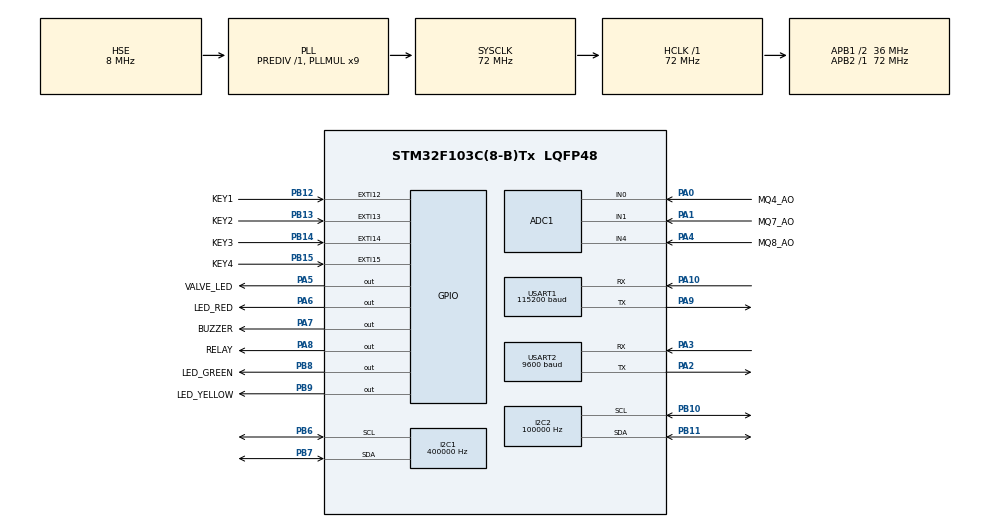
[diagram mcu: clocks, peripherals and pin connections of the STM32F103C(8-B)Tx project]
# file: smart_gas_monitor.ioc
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ADC1.Channel-0\#ChannelRegularConversion=ADC_CHANNEL_0
ADC1.NbrOfConversionFlag=1
ADC1.Rank-0\#ChannelRegularConversion=1
ADC1.SamplingTime-0\#ChannelRegularConversion=ADC_SAMPLETIME_239CYCLES_5
ADC1.master=1
I2C1.ClockSpeed=400000
I2C2.ClockSpeed=100000
Mcu.Family=STM32F1
Mcu.Name=STM32F103C(8-B)Tx
Mcu.Package=LQFP48
NVIC.EXTI15_10_IRQn=true\:0\:0\:false\:false\:true\:false\:true\:true
NVIC.PriorityGroup=NVIC_PRIORITYGROUP_4
NVIC.TIM2_IRQn=true\:1\:0\:false\:false\:true\:false\:true\:true
NVIC.USART1_IRQn=true\:2\:0\:false\:false\:true\:false\:true\:true
NVIC.USART2_IRQn=true\:2\:0\:false\:false\:true\:false\:true\:true
PA0-WKUP.GPIO_Label=MQ4_AO
PA0-WKUP.Signal=ADCx_IN0
PA1.GPIO_Label=MQ7_AO
PA1.Signal=ADCx_IN1
PA10.Mode=Asynchronous
PA10.Signal=USART1_RX
PA13.Mode=Serial_Wire
PA13.Signal=SYS_JTMS-SWDIO
PA14.Mode=Serial_Wire
PA14.Signal=SYS_JTCK-SWCLK
PA2.Mode=Asynchronous
PA2.Signal=USART2_TX
PA3.Mode=Asynchronous
PA3.Signal=USART2_RX
PA4.GPIO_Label=MQ8_AO
PA4.Signal=ADCx_IN4
PA5.GPIO_Label=VALVE_LED
PA5.Signal=GPIO_Output
PA6.GPIO_Label=LED_RED
PA6.Signal=GPIO_Output
PA7.GPIO_Label=BUZZER
PA7.Signal=GPIO_Output
PA8.GPIO_Label=RELAY
PA8.Signal=GPIO_Output
PA9.Mode=Asynchronous
PA9.Signal=USART1_TX
PB10.Mode=I2C
PB10.Signal=I2C2_SCL
PB11.Mode=I2C
PB11.Signal=I2C2_SDA
PB12.GPIO_Label=KEY1
PB12.GPIO_ModeDefaultEXTI=GPIO_MODE_IT_FALLING
PB12.GPIO_PuPd=GPIO_PULLUP
PB12.Signal=GPXTI12
PB13.GPIO_Label=KEY2
PB13.GPIO_ModeDefaultEXTI=GPIO_MODE_IT_FALLING
PB13.GPIO_PuPd=GPIO_PULLUP
PB13.Signal=GPXTI13
PB14.GPIO_Label=KEY3
PB14.GPIO_ModeDefaultEXTI=GPIO_MODE_IT_FALLING
PB14.GPIO_PuPd=GPIO_PULLUP
PB14.Signal=GPXTI14
PB15.GPIO_Label=KEY4
PB15.GPIO_ModeDefaultEXTI=GPIO_MODE_IT_FALLING
PB15.GPIO_PuPd=GPIO_PULLUP
PB15.Signal=GPXTI15
PB6.Mode=I2C
PB6.Signal=I2C1_SCL
PB7.Mode=I2C
PB7.Signal=I2C1_SDA
PB8.GPIO_Label=LED_GREEN
PB8.Signal=GPIO_Output
PB9.GPIO_Label=LED_YELLOW
PB9.Signal=GPIO_Output
PD0-OSC_IN.Mode=HSE-External-Oscillator
PD0-OSC_IN.Signal=RCC_OSC_IN
PD1-OSC_OUT.Mode=HSE-External-Oscillator
PD1-OSC_OUT.Signal=RCC_OSC_OUT
ProjectManager.HeapSize=0x200
ProjectManager.StackSize=0x400
ProjectManager.TargetToolchain=Makefile
RCC.ADCPresc=RCC_ADCPCLK2_DIV6
RCC.AHBFreq_Value=72000000
RCC.APB1CLKDivider=RCC_HCLK_DIV2
RCC.APB1Freq_Value=36000000
RCC.APB1TimFreq_Value=72000000
RCC.APB2Freq_Value=72000000
RCC.APB2TimFreq_Value=72000000
RCC.HCLKFreq_Value=72000000
RCC.PLLMUL=RCC_PLL_MUL9
RCC.PLLSourceVirtual=RCC_PLLSOURCE_HSE
RCC.SYSCLKFreq_VALUE=72000000
RCC.SYSCLKSource=RCC_SYSCLKSOURCE_PLLCLK
RCC.USBFreq_Value=72000000
SH.ADCx_IN0.0=ADC1_IN0,IN0
SH.ADCx_IN1.0=ADC1_IN1,IN1
SH.ADCx_IN4.0=ADC1_IN4,IN4
TIM2.AutoReloadPreload=TIM_AUTORELOAD_PRELOAD_DISABLE
TIM2.ClockDivision=TIM_CLOCKDIVISION_DIV1
TIM2.CounterMode=TIM_COUNTERMODE_UP
TIM2.Period=9999
TIM2.Prescaler=71
USART1.BaudRate=115200
USART1.VirtualMode=VM_ASYNC
USART2.BaudRate=9600
USART2.VirtualMode=VM_ASYNC
VP_TIM2_VS_ClockSourceINT.Mode=Internal
board=custom

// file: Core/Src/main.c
/* USER CODE BEGIN Header */
/**
  ******************************************************************************
  * @file           : main.c
  * @brief          : Main program body
  ******************************************************************************
  * @attention
  *
  * Copyright (c) 2026 STMicroelectronics.
  * All rights reserved.
  *
  * This software is licensed under terms that can be found in the LICENSE file
  * in the root directory of this software component.
  * If no LICENSE file comes with this software, it is provided AS-IS.
  *
  ******************************************************************************
  */
/* USER CODE END Header */
#include "main.h"
#include "adc.h"
#include "i2c.h"
#include "tim.h"
#include "usart.h"
#include "gpio.h"

/* USER CODE BEGIN Includes */
#include "app.h"
/* USER CODE END Includes */

/* USER CODE BEGIN PV */
static app_t app;
/* USER CODE END PV */

void SystemClock_Config(void);

int main(void)
{

  /* MCU Configuration--------------------------------------------------------*/

  /* Reset of all peripherals, Initializes the Flash interface and the Systick. */
  HAL_Init();

  /* Configure the system clock */
  SystemClock_Config();

  /* Initialize all configured peripherals */
  MX_GPIO_Init();
  MX_ADC1_Init();
  MX_I2C1_Init();
  MX_I2C2_Init();
  MX_USART1_UART_Init();
  MX_USART2_UART_Init();
  MX_TIM2_Init();
  /* USER CODE BEGIN 2 */
  if (!app_init(&app, &hadc1, &hi2c2, &hi2c1, &htim2, &huart1, &huart2))
  {
    Error_Handler();
  }
  /* USER CODE END 2 */

  /* Infinite loop */
  while (1)
  {

    /* USER CODE BEGIN 3 */
    app_run(&app);
  }
  /* USER CODE END 3 */
}

void SystemClock_Config(void)
{
  RCC_OscInitTypeDef RCC_OscInitStruct = {0};
  RCC_ClkInitTypeDef RCC_ClkInitStruct = {0};
  RCC_PeriphCLKInitTypeDef PeriphClkInit = {0};

  /** Initializes the RCC Oscillators according to the specified parameters
  * in the RCC_OscInitTypeDef structure.
  */
  RCC_OscInitStruct.OscillatorType = RCC_OSCILLATORTYPE_HSE;
  RCC_OscInitStruct.HSEState = RCC_HSE_ON;
  RCC_OscInitStruct.HSEPredivValue = RCC_HSE_PREDIV_DIV1;
  RCC_OscInitStruct.HSIState = RCC_HSI_ON;
  RCC_OscInitStruct.PLL.PLLState = RCC_PLL_ON;
  RCC_OscInitStruct.PLL.PLLSource = RCC_PLLSOURCE_HSE;
  RCC_OscInitStruct.PLL.PLLMUL = RCC_PLL_MUL9;
  if (HAL_RCC_OscConfig(&RCC_OscInitStruct) != HAL_OK)
  {
    Error_Handler();
  }

  /** Initializes the CPU, AHB and APB buses clocks
  */
  RCC_ClkInitStruct.ClockType = RCC_CLOCKTYPE_HCLK|RCC_CLOCKTYPE_SYSCLK
                              |RCC_CLOCKTYPE_PCLK1|RCC_CLOCKTYPE_PCLK2;
  RCC_ClkInitStruct.SYSCLKSource = RCC_SYSCLKSOURCE_PLLCLK;
  RCC_ClkInitStruct.AHBCLKDivider = RCC_SYSCLK_DIV1;
  RCC_ClkInitStruct.APB1CLKDivider = RCC_HCLK_DIV2;
  RCC_ClkInitStruct.APB2CLKDivider = RCC_HCLK_DIV1;

  if (HAL_RCC_ClockConfig(&RCC_ClkInitStruct, FLASH_LATENCY_2) != HAL_OK)
  {
    Error_Handler();
  }
  PeriphClkInit.PeriphClockSelection = RCC_PERIPHCLK_ADC;
  PeriphClkInit.AdcClockSelection = RCC_ADCPCLK2_DIV6;
  if (HAL_RCCEx_PeriphCLKConfig(&PeriphClkInit) != HAL_OK)
  {
    Error_Handler();
  }
}

void Error_Handler(void)
{
  /* USER CODE BEGIN Error_Handler_Debug */
  __HAL_RCC_GPIOA_CLK_ENABLE();
  alarm_output_force_safe();
  /* User can add his own implementation to report the HAL error return state */
  __disable_irq();
  while (1)
  {
  }
  /* USER CODE END Error_Handler_Debug */
}
